# MMCSD0_SS_CFG register map
Vendor: Texas Instruments
Peripheral module from a debugger description file (folder J7ES).
Registers are 32-bit, access per field, reset 0x0 unless marked. A register's access mark holds for its fields unless they carry their own. Offsets are as the file gives them; lines under a group give offsets from that group; [hi:lo] are bit positions; {n}, {i} and the like mark numbered series; 'fields as' and 'values as' point back to an identical list; <NAME> marks a mode.

## MMCSD0_SS_CFG
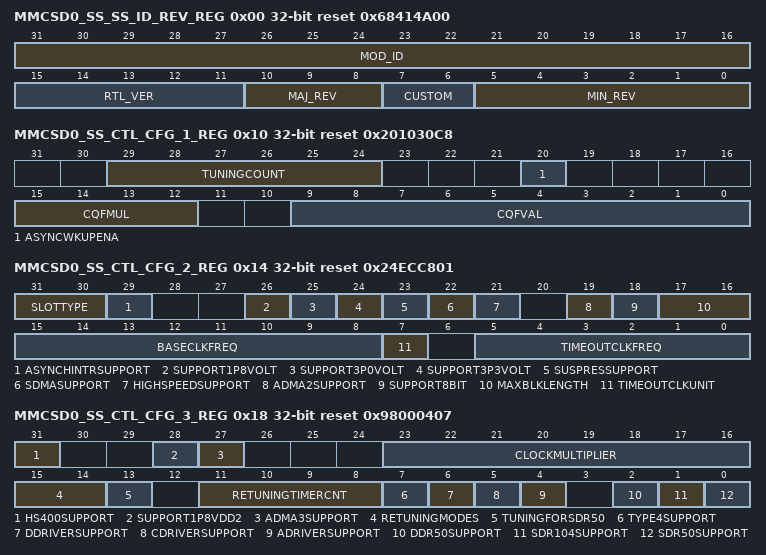
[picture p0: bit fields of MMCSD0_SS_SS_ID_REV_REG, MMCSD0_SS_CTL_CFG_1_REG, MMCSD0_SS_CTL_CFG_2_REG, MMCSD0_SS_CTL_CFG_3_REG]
0x00 MMCSD0_SS_SS_ID_REV_REG ro reset 0x68414A00 — The Subsystem ID and Revision Register contains the module ID, major, and minor revisions for the subsystem.
  [31:16] MOD_ID — Module ID
  [15:11] RTL_VER — RTL Version
  [10:8] MAJ_REV — Major Revision
  [7:6] CUSTOM
  [5:0] MIN_REV — Minor Revision
0x10 MMCSD0_SS_CTL_CFG_1_REG reset 0x201030C8 — The Controller Config 1 Register contains various fields to control the configuration ports on the Host Controller.
  [29:24] TUNINGCOUNT rw — Configures the number of Taps (Phases) of the RX clock that is supported.
  [20] ASYNCWKUPENA rw — Determines the Wakeup Signal Generation Mode.
  [15:12] CQFMUL rw — FMUL for the CQ Internal Timer Clock Frequency
  [9:0] CQFVAL rw — FVAL for the CQ Internal Timer Clock Frequency
0x14 MMCSD0_SS_CTL_CFG_2_REG reset 0x24ECC801 — The Controller Config 2 Register contains various fields to control the configuration ports on the Host Controller. This register sets the LSB fields in the register inside the Host Controller.
  [31:30] SLOTTYPE rw — Slot Type Should be set based on the final product usage.
  [29] ASYNCHINTRSUPPORT rw — Asynchronous Interrupt Support Suggested Value is 1h (The Core supports monitoring of Asynchronous Interrupt).
  [26] SUPPORT1P8VOLT rw — 1.8 V Support Suggested Value is 1h (The 1.8 Volt Switching is supported by Core).
  [25] SUPPORT3P0VOLT rw — 3.0 V Support Should be set based on whether 3.0 V is supported on the SD Interface.
  [24] SUPPORT3P3VOLT rw — 3.3 V Support Suggested Value is 1h as the 3.3 V is the default voltage on the SD Interface.
  [23] SUSPRESSUPPORT rw — Suspend/Resume Support Suggested Value is 1h (The Suspend/Resume is supported by Core).
  [22] SDMASUPPORT rw — SDMA Support Suggested Value is 1h (The SDMA is supported by Core).
  [21] HIGHSPEEDSUPPORT rw — High Speed Support Suggested Value is 1h (The High Speed mode is supported by Core).
  [19] ADMA2SUPPORT rw — ADMA2 Support Suggested Value is 1h (The ADMA2 is supported by Core).
  [18] SUPPORT8BIT rw — 8-bit Support for Embedded Device Suggested Value is 1h (The Core supports 8-bit Interface).
  [17:16] MAXBLKLENGTH rw — Max Block Length Maximum Block Length supported by the Core/Device.
  [15:8] BASECLKFREQ rw — Base Clock Frequency for SD Clock This is the frequency of the xin_clk.
  [7] TIMEOUTCLKUNIT rw — Timeout Clock Unit Suggested Value is 0h (KHz).
  [5:0] TIMEOUTCLKFREQ rw — Timeout Clock Frequency Suggested Value is 1 KHz.
0x18 MMCSD0_SS_CTL_CFG_3_REG reset 0x98000407 — The Controller Config 3 Register contains various fields to control the configuration ports on the Host Controller. This register sets the MSB fields in the register inside the Host Controller.
  [31] HS400SUPPORT rw — HS400 Support Suggested Value is 1h (The Core supports HS400 Mode).
  [28] SUPPORT1P8VDD2 rw — 1.8 V VDD2 Support
  [27] ADMA3SUPPORT rw
  [23:16] CLOCKMULTIPLIER rw — Clock Multiplier This field indicates clock multiplier value of programmable clock generator.
  [15:14] RETUNINGMODES rw — Re-Tuning Modes Should be set to 2h as the Core supports only the Software Timer based Re-Tuning.
  [13] TUNINGFORSDR50 rw — Use Tuning for SDR50 This bit should be set if the application wants Tuning be used for SDR50 Modes.
  [11:8] RETUNINGTIMERCNT rw — Timer Count for Re-Tuning This is the Timer Count for Re-Tuning Timer for Re-Tuning Mode 1 to 3.
  [7] TYPE4SUPPORT rw — Driver Type 4 Support This bit should be set based on whether Driver Type 4 for 1.8 Signalling is supported or not.
  [6] DDRIVERSUPPORT rw — Driver Type D Support This bit should be set based on whether Driver Type D for 1.8 Signalling is supported or not.
  [5] CDRIVERSUPPORT rw — Driver Type C Support This bit should be set based on whether Driver Type C for 1.8 Signalling is supported or not.
  [4] ADRIVERSUPPORT rw — Driver Type A Support This bit should be set based on whether Driver Type A for 1.8 Signalling is supported or not.
  [2] DDR50SUPPORT rw — DDR50 Support Suggested Value is 1h (The Core supports DDR50 mode of operation).
  [1] SDR104SUPPORT rw
  [0] SDR50SUPPORT rw
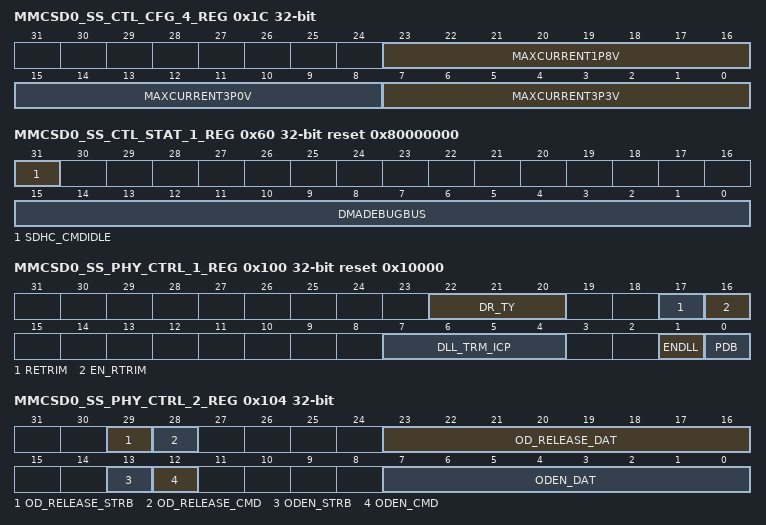
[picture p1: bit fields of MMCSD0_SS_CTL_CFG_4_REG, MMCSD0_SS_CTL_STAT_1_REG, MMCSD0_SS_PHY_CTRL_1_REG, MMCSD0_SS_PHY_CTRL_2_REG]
0x1C MMCSD0_SS_CTL_CFG_4_REG — The Controller Config 4 Register contains various fields to control the configuration ports on the Host Controller. This register sets the LSB fields in the register inside the Host Controller.
  [23:16] MAXCURRENT1P8V rw — Maximum Current For 1.8 V
  [15:8] MAXCURRENT3P0V rw — Maximum Current For 3.0 V
  [7:0] MAXCURRENT3P3V rw — Maximum Current For 3.3 V
0x20 MMCSD0_SS_CTL_CFG_5_REG — The Controller Config 5 Register contains various fields to control the configuration ports on the Host Controller. This register sets the MSB fields in the register inside the Host Controller.
  [7:0] MAXCURRENTVDD2 rw — Maximum Current For 1.8 V (VDD2)
0x24 MMCSD0_SS_CTL_CFG_6_REG reset 0x100 — The Controller Config 6 Register contains various fields to control the configuration ports on the Host Controller. This register sets the fields in the Preset Values registers ( to ) for Initialization inside the Host Controller.
  [12:0] INITPRESETVAL rw — Preset Value For Initialization
0x28 MMCSD0_SS_CTL_CFG_7_REG reset 0x4 — The Controller Config 7 Register contains various fields to control the configuration ports on the Host Controller. This register sets the fields in the Preset Values registers ( to ) for Default Speed inside the Host Controller.
  [12:0] DSPDPRESETVAL rw — Preset Value For Default Speed
0x2C MMCSD0_SS_CTL_CFG_8_REG reset 0x2 — The Controller Config 8 Register contains various fields to control the configuration ports on the Host Controller. This register sets the fields in the Preset Values registers ( to ) for High Speed inside the Host Controller.
  [12:0] HSPDPRESETVAL rw — Preset Value For High Speed
0x30 MMCSD0_SS_CTL_CFG_9_REG reset 0x4 — The Controller Config 9 Register contains various fields to control the configuration ports on the Host Controller. This register sets the fields in the Preset Values registers ( to ) for SDR12 inside the Host Controller.
  [12:0] SDR12PRESETVAL rw — Preset Value For SDR12
0x34 MMCSD0_SS_CTL_CFG_10_REG reset 0x2 — The Controller Config 10 Register contains various fields to control the configuration ports on the Host Controller. This register sets the fields in the Preset Values registers ( to ) for SDR25 inside the Host Controller.
  [12:0] SDR25PRESETVAL rw — Preset Value For SDR25
0x38 MMCSD0_SS_CTL_CFG_11_REG reset 0x1 — The Controller Config 11 Register contains various fields to control the configuration ports on the Host Controller. This register sets the fields in the Preset Values registers ( to ) for SDR50 inside the Host Controller.
  [12:0] SDR50PRESETVAL rw — Preset Value For SDR50
0x3C MMCSD0_SS_CTL_CFG_12_REG — The Controller Config 12 Register contains various fields to control the configuration ports on the Host Controller. This register sets the fields in the Preset Values registers ( to ) for SDR104 inside the Host Controller.
  [12:0] SDR104PRESETVAL rw — Preset Value For SDR104
0x40 MMCSD0_SS_CTL_CFG_13_REG reset 0x2 — The Controller Config 13 Register contains various fields to control the configuration ports on the Host Controller. This register sets the fields in the Preset Values registers ( to ) for DDR50 inside the Host Controller.
  [12:0] DDR50PRESETVAL rw — Preset Value For DDR50
0x44 MMCSD0_SS_CTL_CFG_14_REG reset 0x1 — The Controller Config 14 Register contains various fields to control the configuration ports on the Host Controller. This register sets the fields in the Preset Values registers ( to ) for HS400 inside the Host Controller.
  [12:0] HS400PRESETVAL rw — Preset Value For HS400
0x60 MMCSD0_SS_CTL_STAT_1_REG ro reset 0x80000000 — The Controller Status 1 Register contains various fields to reflect the status of the debug ports on the Host Controller.
  [31] SDHC_CMDIDLE — Idle signal to enable software to gate off the clocks
  [15:0] DMADEBUGBUS — DMA_CTRL Debug Bus
0x64 MMCSD0_SS_CTL_STAT_2_REG ro reset 0x10 — The Controller Status 2 Register contains various fields to reflect the status of the debug ports on the Host Controller.
  [15:0] CMDDEBUGBUS — CMD_CTRL Debug Bus
0x68 MMCSD0_SS_CTL_STAT_3_REG ro — The Controller Status 3 Register contains various fields to reflect the status of the debug ports on the Host Controller.
  [15:0] TXDDEBUGBUS — TXD_CTRL Debug Bus
0x6C MMCSD0_SS_CTL_STAT_4_REG ro — The Controller Status 4 Register contains various fields to reflect the status of the debug ports on the Host Controller.
  [15:0] RXDDEBUGBUS0 — RXD_CTRL Debug Bus (SD CLK)
0x70 MMCSD0_SS_CTL_STAT_5_REG ro reset 0x8 — The Controller Status 5 Register contains various fields to reflect the status of the debug ports on the Host Controller.
  [15:0] RXDDEBUGBUS1 — RXD_CTRL Debug Bus (RX CLK)
0x74 MMCSD0_SS_CTL_STAT_6_REG ro — The Controller Status 6 Register contains various fields to reflect the status of the debug ports on the Host Controller.
  [15:0] TUNDEBUGBUS — TUN_CTRL Debug Bus
0x100 MMCSD0_SS_PHY_CTRL_1_REG reset 0x10000 — The PHY Control 1 Register contains various fields to control the ports on the Host Controller PHY.
  [22:20] DR_TY rw — Drive Source/Sink Impedance Programming 0h: 50 Ohms
  [17] RETRIM rw — Start CALIO Calibration Cycle At positive edge initiates CALIO calibration cycle.
  [16] EN_RTRIM rw — CALIO Enable Enables CALIO, If enabled CALIO will start calibration cycle at phyctrl_pdb positive edge.
  [7:4] DLL_TRM_ICP rw — Analog DLL's Charge Pump Current Trim Programs the analog DLL loop gain.
  [1] ENDLL rw — Enable DLL Enables the analog DLL circuits.
  [0] PDB rw — CALIO S/M Power Down Bar SoC asserts after power up sequence is completed.
0x104 MMCSD0_SS_PHY_CTRL_2_REG — The PHY Control 2 Register contains various fields to control the ports on the Host Controller PHY.
  [29] OD_RELEASE_STRB rw — Disable an internal 4.7 K pull up resistor on STRB line in open drain mode
  [28] OD_RELEASE_CMD rw — Disable an internal 4.7 K pull up resistor on CMD line in open drain mode
  [23:16] OD_RELEASE_DAT rw — Disable an internal 4.7 K pull up resistor on data lines in open drain mode
  [13] ODEN_STRB rw — Open Drain Enable On STRB Lline
  [12] ODEN_CMD rw — Open Drain Enable On CMD Line
  [7:0] ODEN_DAT rw — Open Drain Enable On DAT Lines
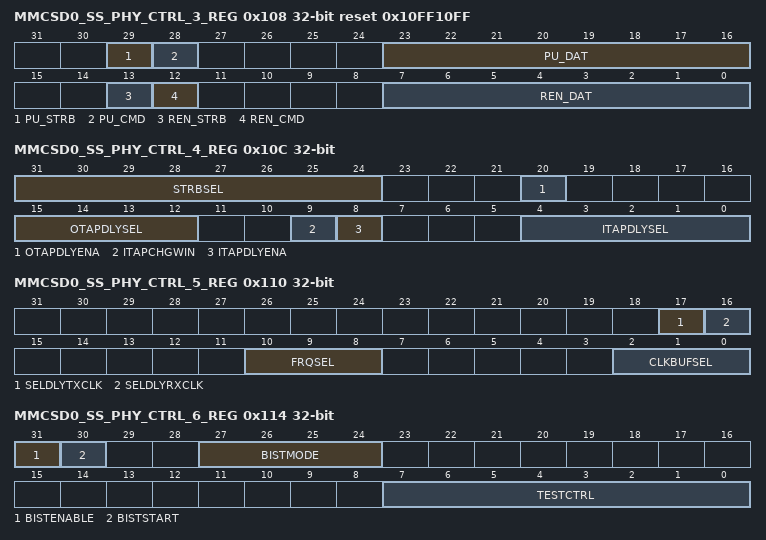
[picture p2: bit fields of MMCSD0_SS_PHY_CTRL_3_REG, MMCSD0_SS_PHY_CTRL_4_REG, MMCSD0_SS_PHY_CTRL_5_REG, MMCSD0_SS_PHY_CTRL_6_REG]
0x108 MMCSD0_SS_PHY_CTRL_3_REG reset 0x10FF10FF — The PHY Control 3 Register contains various fields to control the ports on the Host Controller PHY.
  [29] PU_STRB rw — Enable Pull Up On STRB Line If ren_strb is high week pull up is enabled on STRB line.
  [28] PU_CMD rw — Enable Pull Up On CMD Line If ren_cmd is high week pull up is enabled on CMD line.
  [23:16] PU_DAT rw — Enable Pull Up On DAT Lines If ren_dat is high week pull up is enabled on DATA lines.
  [13] REN_STRB rw — Enable Pull Up/Down On The STRB Line If pu_strb is high a week pull up is enabled on STRB line, if low week pull down is enabled on STRB line.
  [12] REN_CMD rw — Enable Pull Up/Down On The CMD Line If pu_cmd is high a week pull up is enabled on CMD line, if low week pull down is enabled on CMD line.
  [7:0] REN_DAT rw — Enable Pull Up/Down On The DAT Lines If pu_dat is high a week pull up is enabled on DATA lines, if low week pull down is enabled on DATA lines.
0x10C MMCSD0_SS_PHY_CTRL_4_REG — The PHY Control 4 Register contains various fields to control the ports on the Host Controller PHY.
  [31:24] STRBSEL rw — Select the Four Taps for each of STRB_90 and STRB_180 Outputs.
  [20] OTAPDLYENA rw — Output Tap Delay Enable Enables manual control of the TX clock tap delay, for clocking the final stage flops for maintaining Hold requirements on EMMC Interface.
  [15:12] OTAPDLYSEL rw — Output Tap Delay Select Manual control of the TX clock tap delay for clocking the final stage flops for maintaining Hold requirements on EMMC Interface.
  [9] ITAPCHGWIN rw — Input Tap Change Window It gets asserted by the controller while changing the itapdlysel.
  [8] ITAPDLYENA rw — Input Tap Delay Enable This is used for the manual control of the RX clock Tap Delay in non HS200/HS400 modes.
  [4:0] ITAPDLYSEL rw — Input Tap Delay Select Manual control of the RX clock Tap Delay in the non HS200/HS400 modes.
0x110 MMCSD0_SS_PHY_CTRL_5_REG — The PHY Control 5 Register contains various fields to control the ports on the Host Controller PHY.
  [17] SELDLYTXCLK rw — Select the Delay chain based txclk.
  [16] SELDLYRXCLK rw — Select the Delay chain based rxclk.
  [10:8] FRQSEL rw — Select the frequency range of DLL operation:
  [2:0] CLKBUFSEL rw — Clock Delay Buffer Select.
0x114 MMCSD0_SS_PHY_CTRL_6_REG — The PHY Control 6 Register contains various fields to control the ports on the Host Controller PHY.
  [31] BISTENABLE rw — Internal BIST Operation Enable Enables the embedded BIST.
  [30] BISTSTART rw — Internal BIST Start Starts the embedded BIST operation.
  [27:24] BISTMODE rw — Internal BIST Mode Select Select the embedded BIST mode of operation.
  [7:0] TESTCTRL rw — PHY Test Control:
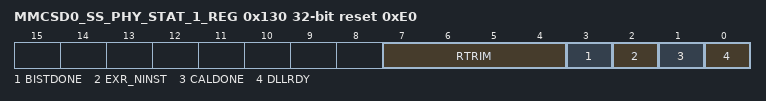
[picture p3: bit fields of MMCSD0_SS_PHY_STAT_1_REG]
0x130 MMCSD0_SS_PHY_STAT_1_REG ro reset 0xE0 — The PHY Status 1 Register contains various fields to reflect the status of the Host Controller PHY ports.
  [7:4] RTRIM — CALIO Calibration Result Holds the content of CALIO Impedance Calibration Result.
  [3] BISTDONE — Internal BIST Completed Test Cycle Indicates that the embedded BIST has completed the test cycle.
  [2] EXR_NINST — External Resistor On CALIO Absent Indicates trim cycle started and external resistor is absent.
  [1] CALDONE — STATUS, indicate that CALIO Calibration is completed successfully.
  [0] DLLRDY — DLL Ready Indicates that DLL loop is locked.
0x134 MMCSD0_SS_PHY_STAT_2_REG ro — The PHY Status 2 Register contains various fields to reflect the status of the Host Controller PHY ports.
  [31:0] BISTSTATUS — Internal BIST Data Compare Results BIST cycle data comparison results.
